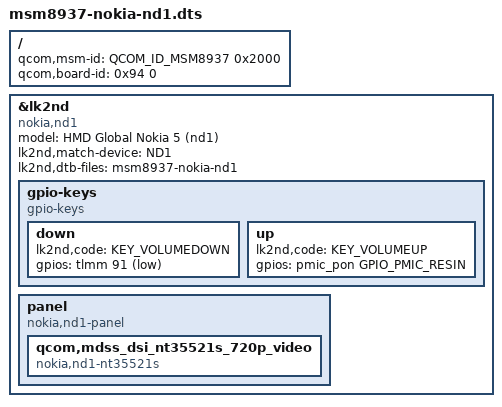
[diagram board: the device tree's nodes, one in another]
// SPDX-License-Identifier: BSD-3-Clause

#include <skeleton64.dtsi>
#include <lk2nd.dtsi>

/ {
	qcom,msm-id = <QCOM_ID_MSM8937 0x2000>;
	qcom,board-id = <0x94 0>;
};

&lk2nd {
	model = "HMD Global Nokia 5 (nd1)";
	compatible = "nokia,nd1";
	lk2nd,match-device = "ND1";
	lk2nd,dtb-files = "msm8937-nokia-nd1";

	gpio-keys {
		compatible = "gpio-keys";

		down {
			lk2nd,code = <KEY_VOLUMEDOWN>;
			gpios = <&tlmm 91 (GPIO_ACTIVE_LOW | GPIO_PULL_UP)>;
		};

		up {
			lk2nd,code = <KEY_VOLUMEUP>;
			gpios = <&pmic_pon GPIO_PMIC_RESIN 0>;
		};
	};

	panel {
		compatible = "nokia,nd1-panel", "lk2nd,panel";

		qcom,mdss_dsi_nt35521s_720p_video {
			compatible = "nokia,nd1-nt35521s";
		};
	};
};
